VERSION ""

NS_ :

BS_:

BU_:

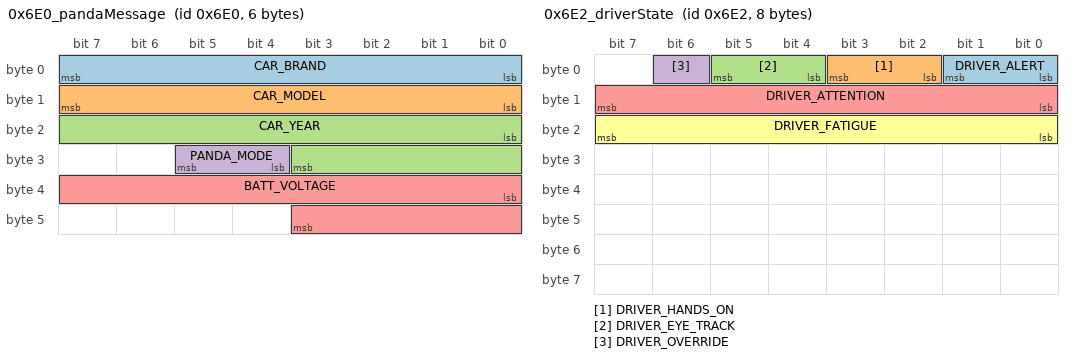
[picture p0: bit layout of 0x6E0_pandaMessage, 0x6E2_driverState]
BO_ 1760 0x6E0_pandaMessage: 6 Vector__XXX
 SG_ CAR_BRAND : 0|8@1+ (1,0) [0|255] "" Vector__XXX
 SG_ CAR_MODEL : 8|8@1+ (1,0) [0|255] "" Vector__XXX
 SG_ CAR_YEAR : 16|12@1+ (1,0) [0|4095] "" Vector__XXX
 SG_ PANDA_MODE : 28|2@1+ (1,0) [0|3] "" Vector__XXX
 SG_ BATT_VOLTAGE : 32|12@1+ (0.01,0) [0|40.95] "V" Vector__XXX

BO_ 1761 0x6E1_userCommand: 8 Vector__XXX
 SG_ BRAKE_PEDAL : 0|8@1+ (0.4,0) [0|102] "%" Vector__XXX
 SG_ GAS_PEDAL : 8|8@1+ (0.4,0) [0|102] "%" Vector__XXX
 SG_ STEER_ANGLE : 16|16@1+ (0.1,0) [-780|780] "deg" Vector__XXX
 SG_ YAW_RATE : 32|14@1+ (0.01,-81.91) [-81.91|81.91] "deg/s" Vector__XXX
 SG_ CRUISE_ENABLE : 46|1@1+ (1,0) [0|1] "" Vector__XXX
 SG_ LANE_ENABLE : 47|1@1+ (1,0) [0|1] "" Vector__XXX
 SG_ MADS_BUTTON : 48|1@1+ (1,0) [0|1] "" Vector__XXX
 SG_ CRUISE_SET : 49|1@1+ (1,0) [0|1] "" Vector__XXX
 SG_ CRUISE_CANCEL : 50|1@1+ (1,0) [0|1] "" Vector__XXX
 SG_ CRUISE_RESUME : 51|1@1+ (1,0) [0|1] "" Vector__XXX
 SG_ SPEED_UP_BTN : 52|1@1+ (1,0) [0|1] "" Vector__XXX
 SG_ SPEED_DOWN_BTN : 53|1@1+ (1,0) [0|1] "" Vector__XXX
 SG_ DISTANCE_NEAR_BTN : 54|1@1+ (1,0) [0|1] "" Vector__XXX
 SG_ DISTANCE_FAR_BTN : 55|1@1+ (1,0) [0|1] "" Vector__XXX
 SG_ HAZARD_BTN : 56|1@1+ (1,0) [0|1] "" Vector__XXX
 SG_ LEFT_BLINKER_BTN : 57|1@1+ (1,0) [0|1] "" Vector__XXX
 SG_ RIGHT_BLINKER_BTN : 58|1@1+ (1,0) [0|1] "" Vector__XXX
 SG_ ACCEL_PEDAL_PRESSED : 59|1@1+ (1,0) [0|1] "" Vector__XXX
 SG_ BRAKE_PEDAL_PRESSED : 60|1@1+ (1,0) [0|1] "" Vector__XXX
 SG_ STEER_WHEEL_PRESSED : 61|1@1+ (1,0) [0|1] "" Vector__XXX

BO_ 1762 0x6E2_driverState: 8 Vector__XXX
 SG_ DRIVER_ALERT : 0|2@1+ (1,0) [0|3] "" Vector__XXX
 SG_ DRIVER_HANDS_ON : 2|2@1+ (1,0) [0|3] "" Vector__XXX
 SG_ DRIVER_EYE_TRACK : 4|2@1+ (1,0) [0|3] "" Vector__XXX
 SG_ DRIVER_OVERRIDE : 6|1@1+ (1,0) [0|1] "" Vector__XXX
 SG_ DRIVER_ATTENTION : 8|8@1+ (0.4,0) [0|102] "%" Vector__XXX
 SG_ DRIVER_FATIGUE : 16|8@1+ (0.4,0) [0|102] "%" Vector__XXX

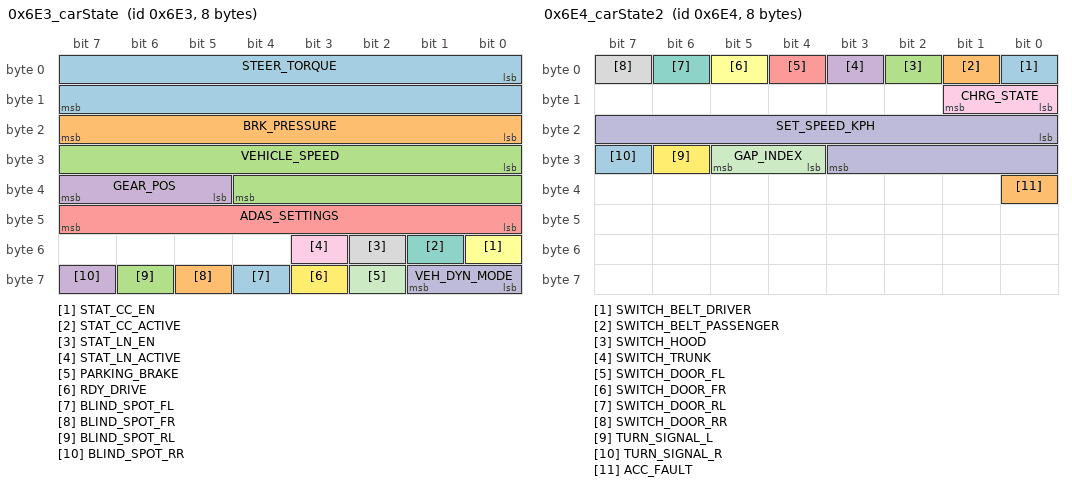
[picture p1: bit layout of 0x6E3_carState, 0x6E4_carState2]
BO_ 1763 0x6E3_carState: 8 Vector__XXX
 SG_ STEER_TORQUE : 0|16@1+ (0.1,-3276.8) [-3276.8|3276.7] "Nm" Vector__XXX
 SG_ BRK_PRESSURE : 16|8@1+ (0.1,0) [0|25.5] "bar" Vector__XXX
 SG_ VEHICLE_SPEED : 24|13@1+ (0.05625,0) [0|360] "km/h" Vector__XXX
 SG_ GEAR_POS : 37|3@1+ (1,0) [0|7] "" Vector__XXX
 SG_ ADAS_SETTINGS : 40|8@1+ (1,0) [0|255] "" Vector__XXX
 SG_ STAT_CC_EN : 48|1@1+ (1,0) [0|1] "" Vector__XXX
 SG_ STAT_CC_ACTIVE : 49|1@1+ (1,0) [0|1] "" Vector__XXX
 SG_ STAT_LN_EN : 50|1@1+ (1,0) [0|1] "" Vector__XXX
 SG_ STAT_LN_ACTIVE : 51|1@1+ (1,0) [0|1] "" Vector__XXX
 SG_ VEH_DYN_MODE : 56|2@1+ (1,0) [0|3] "" Vector__XXX
 SG_ PARKING_BRAKE : 58|1@1+ (1,0) [0|1] "" Vector__XXX
 SG_ RDY_DRIVE : 59|1@1+ (1,0) [0|1] "" Vector__XXX
 SG_ BLIND_SPOT_FL : 60|1@1+ (1,0) [0|1] "" Vector__XXX
 SG_ BLIND_SPOT_FR : 61|1@1+ (1,0) [0|1] "" Vector__XXX
 SG_ BLIND_SPOT_RL : 62|1@1+ (1,0) [0|1] "" Vector__XXX
 SG_ BLIND_SPOT_RR : 63|1@1+ (1,0) [0|1] "" Vector__XXX

BO_ 1764 0x6E4_carState2: 8 Vector__XXX
 SG_ SWITCH_BELT_DRIVER : 0|1@1+ (1,0) [0|1] "" Vector__XXX
 SG_ SWITCH_BELT_PASSENGER : 1|1@1+ (1,0) [0|1] "" Vector__XXX
 SG_ SWITCH_HOOD : 2|1@1+ (1,0) [0|1] "" Vector__XXX
 SG_ SWITCH_TRUNK : 3|1@1+ (1,0) [0|1] "" Vector__XXX
 SG_ SWITCH_DOOR_FL : 4|1@1+ (1,0) [0|1] "" Vector__XXX
 SG_ SWITCH_DOOR_FR : 5|1@1+ (1,0) [0|1] "" Vector__XXX
 SG_ SWITCH_DOOR_RL : 6|1@1+ (1,0) [0|1] "" Vector__XXX
 SG_ SWITCH_DOOR_RR : 7|1@1+ (1,0) [0|1] "" Vector__XXX
 SG_ CHRG_STATE : 8|2@1+ (1,0) [0|3] "" Vector__XXX
 SG_ SET_SPEED_KPH : 16|12@1+ (0.1,0) [0|409.5] "km/h" Vector__XXX
 SG_ GAP_INDEX : 28|2@1+ (1,1) [1|4] "" Vector__XXX
 SG_ TURN_SIGNAL_L : 30|1@1+ (1,0) [0|1] "" Vector__XXX
 SG_ TURN_SIGNAL_R : 31|1@1+ (1,0) [0|1] "" Vector__XXX
 SG_ ACC_FAULT : 32|1@1+ (1,0) [0|1] "" Vector__XXX

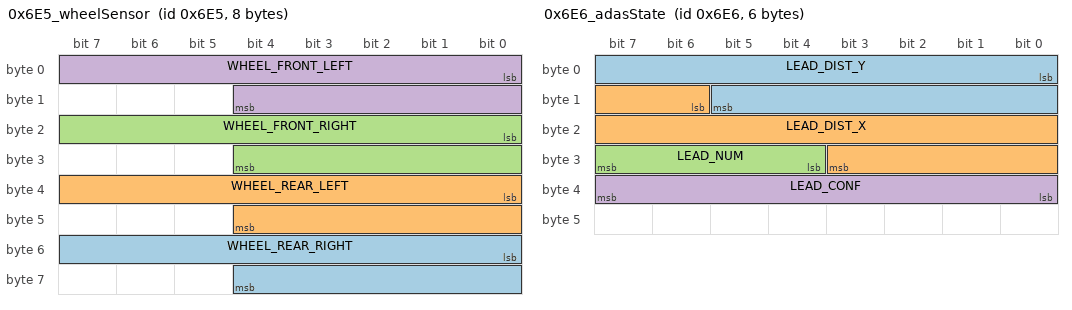
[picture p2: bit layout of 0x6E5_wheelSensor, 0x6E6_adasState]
BO_ 1765 0x6E5_wheelSensor: 8 Vector__XXX
 SG_ WHEEL_REAR_RIGHT : 48|13@1+ (0.05625,0) [0|360] "km/h" Vector__XXX
 SG_ WHEEL_REAR_LEFT : 32|13@1+ (0.05625,0) [0|360] "km/h" Vector__XXX
 SG_ WHEEL_FRONT_RIGHT : 16|13@1+ (0.05625,0) [0|360] "km/h" Vector__XXX
 SG_ WHEEL_FRONT_LEFT : 0|13@1+ (0.05625,0) [0|360] "km/h" Vector__XXX

BO_ 1766 0x6E6_adasState: 6 Vector__XXX
 SG_ LEAD_DIST_Y : 0|14@1+ (0.04,0) [0|655.32] "m" Vector__XXX
 SG_ LEAD_DIST_X : 14|14@1+ (0.04,0) [0|655.32] "m" Vector__XXX
 SG_ LEAD_NUM : 28|4@1+ (1,0) [0|3] "" Vector__XXX
 SG_ LEAD_CONF : 32|8@1+ (0.4,0) [0|102] "%" Vector__XXX

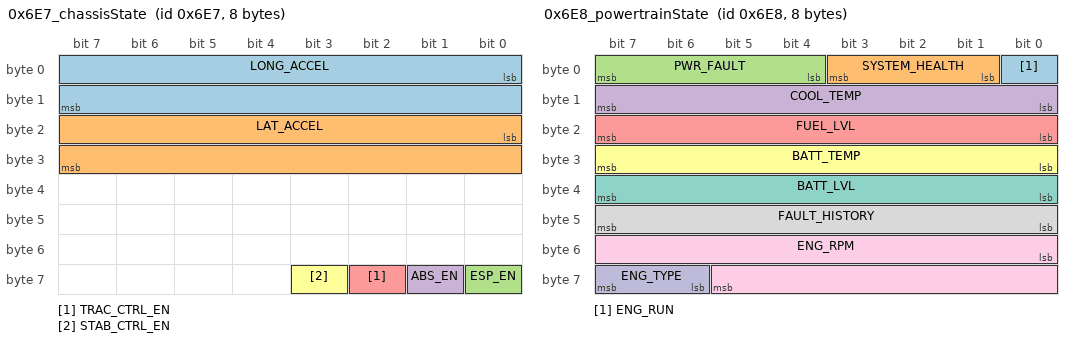
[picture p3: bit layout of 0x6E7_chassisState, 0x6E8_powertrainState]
BO_ 1767 0x6E7_chassisState: 8 Vector__XXX
 SG_ LONG_ACCEL : 0|16@1+ (0.001,-32.768) [-32.768|32.767] "m/s2" Vector__XXX
 SG_ LAT_ACCEL : 16|16@1+ (0.001,-32.768) [-32.768|32.767] "m/s2" Vector__XXX
 SG_ ESP_EN : 56|1@1+ (1,0) [0|1] "" Vector__XXX
 SG_ ABS_EN : 57|1@1+ (1,0) [0|1] "" Vector__XXX
 SG_ TRAC_CTRL_EN : 58|1@1+ (1,0) [0|1] "" Vector__XXX
 SG_ STAB_CTRL_EN : 59|1@1+ (1,0) [0|1] "" Vector__XXX

BO_ 1768 0x6E8_powertrainState: 8 Vector__XXX
 SG_ ENG_RUN : 0|1@1+ (1,0) [0|1] "" Vector__XXX
 SG_ SYSTEM_HEALTH : 1|3@1+ (1,0) [0|7] "" Vector__XXX
 SG_ PWR_FAULT : 4|4@1+ (1,0) [0|15] "" Vector__XXX
 SG_ COOL_TEMP : 8|8@1+ (1,-40) [-40|215] "C" Vector__XXX
 SG_ FUEL_LVL : 16|8@1+ (0.4,0) [0|102] "%" Vector__XXX
 SG_ BATT_TEMP : 24|8@1+ (1,-40) [-40|215] "C" Vector__XXX
 SG_ BATT_LVL : 32|8@1+ (0.4,0) [0|102] "%" Vector__XXX
 SG_ FAULT_HISTORY : 40|8@1+ (1,0) [0|255] "" Vector__XXX
 SG_ ENG_RPM : 48|14@1+ (0.25,0) [0|4095.75] "rpm" Vector__XXX
 SG_ ENG_TYPE : 62|2@1+ (1,0) [0|3] "" Vector__XXX

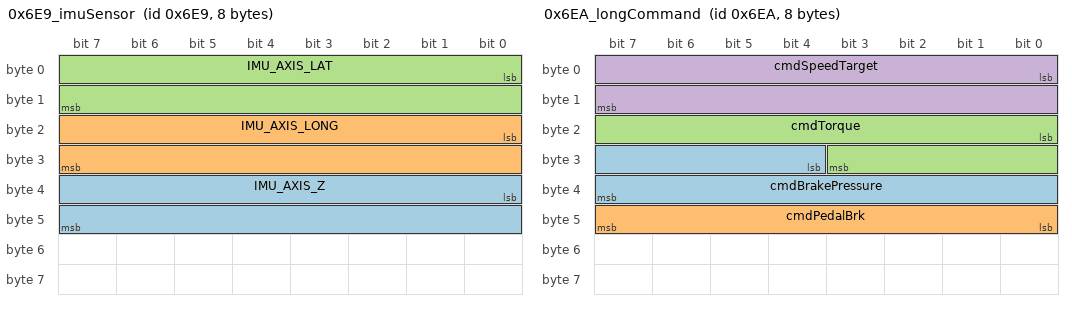
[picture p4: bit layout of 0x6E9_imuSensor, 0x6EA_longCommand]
BO_ 1769 0x6E9_imuSensor: 8 Vector__XXX
 SG_ IMU_AXIS_Z : 32|16@1+ (0.001,-32.768) [-32.768|32.767] "m/s2" Vector__XXX
 SG_ IMU_AXIS_LONG : 16|16@1+ (0.001,-32.768) [-32.768|32.767] "m/s2" Vector__XXX
 SG_ IMU_AXIS_LAT : 0|16@1+ (0.001,-32.768) [-32.768|32.767] "m/s2" Vector__XXX

BO_ 1770 0x6EA_longCommand: 8 Vector__XXX
 SG_ cmdBrakePressure : 28|12@1+ (0.015625,0) [0|1023.984375] "bar" Vector__XXX
 SG_ cmdPedalBrk : 40|8@1+ (0.4,0) [0|102] "%" Vector__XXX
 SG_ cmdTorque : 16|12@1+ (5,-5000) [-5000|15475] "NM" Vector__XXX
 SG_ cmdSpeedTarget : 0|16@1+ (0.01,0) [0|655.35] "km/h" Vector__XXX

BO_ 1771 0x6EB_longCommand2: 8 Vector__XXX
 SG_ cmdSpeedAccel : 0|8@1+ (0.05,-10) [-10|2.75] "m/s2" Vector__XXX
 SG_ cmdSpeedDecel : 8|8@1+ (0.05,-10) [-10|2.75] "m/s2" Vector__XXX
 SG_ cmdAccelTune : 16|4@1+ (1,0) [0|15] "" Vector__XXX
 SG_ cmdDecelTune : 20|4@1+ (1,0) [0|15] "" Vector__XXX
 SG_ cmdCruiseEnabled : 56|1@1+ (1,0) [0|1] "" Vector__XXX
 SG_ cmdCruiseActive : 57|1@1+ (1,0) [0|1] "" Vector__XXX
 SG_ cmdCruiseResume : 58|1@1+ (1,0) [0|1] "" Vector__XXX
 SG_ cmdCruiseSsEn : 59|1@1+ (1,0) [0|1] "" Vector__XXX
 SG_ cmdCruiseSsActive : 60|1@1+ (1,0) [0|1] "" Vector__XXX
 SG_ cmdRegenEn : 61|1@1+ (1,0) [0|1] "" Vector__XXX
 SG_ cmdRegenKer : 62|2@1+ (1,0) [0|3] "" Vector__XXX
 SG_ cmdAccControllable : 55|1@1+ (1,0) [0|1] "" Vector__XXX
 SG_ cmdAccOverride : 54|1@1+ (1,0) [0|1] "" Vector__XXX
 SG_ cmdStandstillResume : 53|1@1+ (1,0) [0|1] "" Vector__XXX
 SG_ cmdReqActiveLow : 52|1@1+ (1,0) [0|1] "" Vector__XXX
 SG_ cmdIdleStopEn : 51|1@1+ (1,0) [0|1] "" Vector__XXX
 SG_ cmdBrakeComp : 24|8@1+ (0.0039216,0) [0|1] "" Vector__XXX
 SG_ cmdFcwAlert : 32|1@1+ (1,0) [0|1] "" Vector__XXX
 SG_ cmdAebReq : 33|1@1+ (1,0) [0|1] "" Vector__XXX
 SG_ cmdBrakePump : 34|1@1+ (1,0) [0|1] "" Vector__XXX

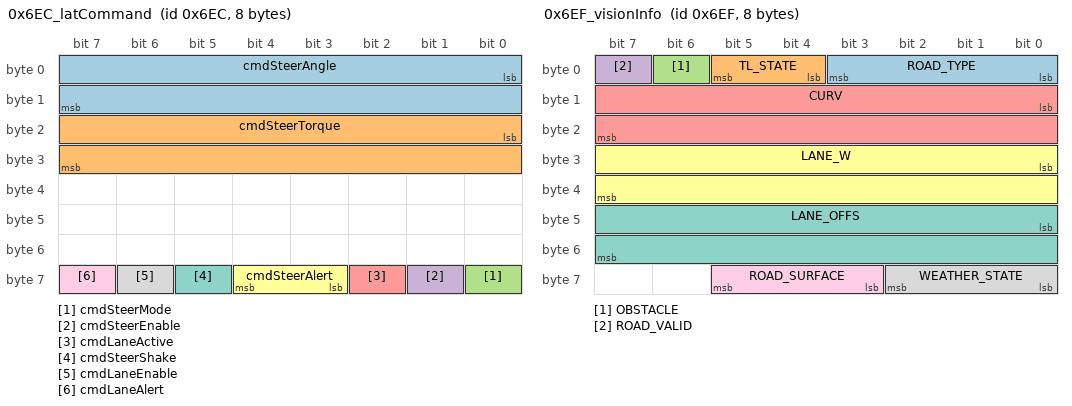
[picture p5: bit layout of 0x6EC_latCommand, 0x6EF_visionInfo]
BO_ 1772 0x6EC_latCommand: 8 Vector__XXX
 SG_ cmdSteerAngle : 0|16@1+ (0.1,-3276.8) [-3276.8|3276.7] "deg" Vector__XXX
 SG_ cmdSteerTorque : 16|16@1+ (0.01,-327.68) [-327.68|327.67] "Nm" Vector__XXX
 SG_ cmdSteerMode : 56|1@1+ (1,0) [0|1] "" Vector__XXX
 SG_ cmdSteerEnable : 57|1@1+ (1,0) [0|1] "" Vector__XXX
 SG_ cmdLaneActive : 58|1@1+ (1,0) [0|1] "" Vector__XXX
 SG_ cmdSteerAlert : 59|2@1+ (1,0) [0|3] "" Vector__XXX
 SG_ cmdSteerShake : 61|1@1+ (1,0) [0|1] "" Vector__XXX
 SG_ cmdLaneEnable : 62|1@1+ (1,0) [0|1] "" Vector__XXX
 SG_ cmdLaneAlert : 63|1@1+ (1,0) [0|1] "" Vector__XXX

BO_ 1776 0x6F0_latCommand2: 8 Vector__XXX

BO_ 1777 0x6F1_dispCommand: 8 Vector__XXX
 SG_ cmdDispCcEn : 0|1@1+ (1,0) [0|1] "" Vector__XXX
 SG_ cmdDispCcActive : 1|1@1+ (1,0) [0|1] "" Vector__XXX
 SG_ cmdDispLnEn : 2|1@1+ (1,0) [0|1] "" Vector__XXX
 SG_ cmdDispLnActive : 3|1@1+ (1,0) [0|1] "" Vector__XXX
 SG_ cmdDispSoundAlert : 4|1@1+ (1,0) [0|1] "" Vector__XXX
 SG_ cmdDispLeadC : 5|1@1+ (1,0) [0|1] "" Vector__XXX
 SG_ cmdDispLeadR : 6|1@1+ (1,0) [0|1] "" Vector__XXX
 SG_ cmdDispLeadL : 7|1@1+ (1,0) [0|1] "" Vector__XXX
 SG_ cmdDispDepartLeft : 8|1@1+ (1,0) [0|1] "" Vector__XXX
 SG_ cmdDispDepartRight : 9|1@1+ (1,0) [0|1] "" Vector__XXX
 SG_ cmdDispLane1 : 10|1@1+ (1,0) [0|1] "" Vector__XXX
 SG_ cmdDispLane2 : 11|1@1+ (1,0) [0|1] "" Vector__XXX
 SG_ cmdDispLane3 : 12|1@1+ (1,0) [0|1] "" Vector__XXX
 SG_ cmdDispLane4 : 13|1@1+ (1,0) [0|1] "" Vector__XXX
 SG_ cmdDispRoadEdgeLeft : 14|1@1+ (1,0) [0|1] "" Vector__XXX
 SG_ cmdDispRoadEdgeRight : 15|1@1+ (1,0) [0|1] "" Vector__XXX
 SG_ cmdDispFollowDistance : 16|2@1+ (1,0) [0|7] "" Vector__XXX
 SG_ cmdDispSpeed : 32|16@1+ (0.01,0) [0|655.35] "km/h" Vector__XXX
 SG_ cmdDispPassThrough : 48|16@1+ (1,0) [0|65535] "" Vector__XXX

BO_ 1775 0x6EF_visionInfo: 8 Vector__XXX
 SG_ ROAD_TYPE : 0|4@1+ (1,0) [0|15] "" Vector__XXX
 SG_ TL_STATE : 4|2@1+ (1,0) [0|3] "" Vector__XXX
 SG_ OBSTACLE : 6|1@1+ (1,0) [0|1] "" Vector__XXX
 SG_ ROAD_VALID : 7|1@1+ (1,0) [0|1] "" Vector__XXX
 SG_ CURV : 8|16@1+ (0.0001,-3.2768) [-3.2768|3.2767] "1/m" Vector__XXX
 SG_ LANE_W : 24|16@1+ (0.01,0) [0|655.35] "m" Vector__XXX
 SG_ LANE_OFFS : 40|16@1+ (0.01,-327.68) [-327.68|327.67] "m" Vector__XXX
 SG_ WEATHER_STATE : 56|3@1+ (1,0) [0|7] "" Vector__XXX
 SG_ ROAD_SURFACE : 59|3@1+ (1,0) [0|7] "" Vector__XXX

BO_ 1773 0x6ED_modelIdAtto3: 6 Vector__XXX
 SG_ MODEL_MARKER : 0|8@1+ (1,0) [0|255] "" Vector__XXX

BO_ 1774 0x6EE_modelIdDolphin: 4 Vector__XXX
 SG_ MODEL_MARKER : 0|8@1+ (1,0) [0|255] "" Vector__XXX

BO_ 1775 0x6EF_modelIdDeepal: 8 Vector__XXX
 SG_ MODEL_MARKER : 0|8@1+ (1,0) [0|255] "" Vector__XXX

BA_DEF_  "BusType" STRING ;
BA_DEF_  "DBName" STRING ;
BA_DEF_ BO_  "GenMsgCycleTime" INT 0 3600000;
BA_DEF_ SG_  "GenSigStartValue" FLOAT 0 0;
BA_DEF_DEF_  "BusType" "CAN";
BA_DEF_DEF_  "DBName" "BROWNPANDA";
BA_DEF_DEF_  "GenMsgCycleTime" 100;
BA_DEF_DEF_  "GenSigStartValue" 0;
BA_ "GenMsgCycleTime" BO_ 1761 10;
BA_ "GenMsgCycleTime" BO_ 1762 20;
BA_ "GenMsgCycleTime" BO_ 1763 10;
BA_ "GenMsgCycleTime" BO_ 1764 20;
BA_ "GenMsgCycleTime" BO_ 1765 50;
BA_ "GenMsgCycleTime" BO_ 1767 50;
BA_ "GenMsgCycleTime" BO_ 1768 20;
BA_ "GenMsgCycleTime" BO_ 1769 10;
BA_ "GenMsgCycleTime" BO_ 1770 10;
BA_ "GenMsgCycleTime" BO_ 1771 20;
BA_ "GenMsgCycleTime" BO_ 1772 10;
BA_ "GenMsgCycleTime" BO_ 1773 1000;
BA_ "GenMsgCycleTime" BO_ 1774 1000;
BA_ "GenMsgCycleTime" BO_ 1775 1000;
BA_ "GenMsgCycleTime" BO_ 1776 20;
BA_ "GenMsgCycleTime" BO_ 1777 20;
BA_ "GenSigStartValue" SG_ 1770 cmdTorque 1000;
BA_ "GenSigStartValue" SG_ 1771 cmdSpeedAccel -455.36;
BA_ "GenSigStartValue" SG_ 1771 cmdSpeedDecel -455.36;
VAL_ 1760 carBrand 0 "UNKNOWN" 1 "BYD" 2 "CHANGAN" 3 "GWM" 4 "GAC" 5 "SAIC" 6 "CHERY" 7 "ZEEKR" 8 "BAIC" 9 "TOYOTA" 10 "ISUZU" 11 "HONDA" 12 "MITSUBISHI" 13 "MERCEDES" 14 "BMW" 15 "PORSCHE" ;
VAL_ 1760 carModel 0 "UNKNOWN" 1 "BYD_SEAL" 2 "BYD_HAN" 3 "BYD_TANG" 4 "CHANGAN_UNI" 5 "GWM_ORA" 6 "GAC_AION" 7 "SAIC_MG" 8 "CHERY_TIGGO" 9 "ZEEKR_001" 10 "BAIC_EU" 11 "TOYOTA_CAMRY" 12 "ISUZU_DMAX" 13 "HONDA_ACCORD" 14 "MITSUBISHI_OUTLANDER" 15 "MERCEDES_C_CLASS" 16 "BMW_3_SERIES" 17 "PORSCHE_TAYCAN" ;
VAL_ 1760 pandaMode 0 "OEM_MODE" 1 "INTERRUPT_MODE" 2 "OVERRIDE_MODE" 3 "DIAGNOSTIC_MODE" ;
VAL_ 1761 CRUISE_ENABLE 0 "NOT_PRESSED" 1 "PRESSED" ;
VAL_ 1761 LANE_ENABLE 0 "NOT_PRESSED" 1 "PRESSED" ;
VAL_ 1761 MADS_BUTTON 0 "NOT_PRESSED" 1 "PRESSED" ;
VAL_ 1761 CRUISE_SET 0 "NOT_PRESSED" 1 "PRESSED" ;
VAL_ 1761 CRUISE_CANCEL 0 "NOT_PRESSED" 1 "PRESSED" ;
VAL_ 1761 CRUISE_RESUME 0 "NOT_PRESSED" 1 "PRESSED" ;
VAL_ 97 btnSpdUp 0 "NOT_PRESSED" 1 "PRESSED" ;
VAL_ 97 btnSpdDn 0 "NOT_PRESSED" 1 "PRESSED" ;
VAL_ 97 btnDistNr 0 "NOT_PRESSED" 1 "PRESSED" ;
VAL_ 97 btnDistFar 0 "NOT_PRESSED" 1 "PRESSED" ;
VAL_ 97 btnHazard 0 "OFF" 1 "ON" ;
VAL_ 97 btnBlinkL 0 "OFF" 1 "ON" ;
VAL_ 97 btnBlinkR 0 "OFF" 1 "ON" ;
VAL_ 97 actPedalPressed 0 "NOT_PRESSED" 1 "PRESSED" ;
VAL_ 97 actBrakePressed 0 "NOT_PRESSED" 1 "PRESSED" ;
VAL_ 97 actSteerPressed 0 "NOT_PRESSED" 1 "PRESSED" ;
VAL_ 98 driverAlert 0 "CRITICAL" 1 "WARNING" 2 "ATTENTION" 3 "NORMAL" ;
VAL_ 98 driverHandsOn 0 "HANDS_OFF" 1 "LIGHT_GRIP" 2 "FIRM_GRIP" 3 "TIGHT_GRIP" ;
VAL_ 98 driverEyeTrack 0 "EYES_OFF" 1 "DISTRACTED" 2 "FOCUSED" 3 "ALERT" ;
VAL_ 98 driverOverride 0 "NO_OVERRIDE" 1 "OVERRIDE_ACTIVE" ;
VAL_ 99 gearPos 0 "PARK" 1 "REVERSE" 2 "NEUTRAL" 3 "DRIVE" 4 "SPORT" 5 "LOW" 6 "MANUAL" 7 "RESERVED" ;
VAL_ 99 statCcEn 0 "DISABLED" 1 "ENABLED" ;
VAL_ 99 statCcActive 0 "INACTIVE" 1 "ACTIVE" ;
VAL_ 99 statLnEn 0 "DISABLED" 1 "ENABLED" ;
VAL_ 99 statLnActive 0 "INACTIVE" 1 "ACTIVE" ;
VAL_ 99 vehDynMode 0 "NORMAL" 1 "ECO" 2 "SPORT" 3 "OTHERS" ;
VAL_ 99 parkingBrake 0 "RELEASED" 1 "ENGAGED" ;
VAL_ 99 rdyDrive 0 "NOT_READY" 1 "READY" ;
VAL_ 99 blindSpotFL 0 "NO_VEHICLE" 1 "VEHICLE_DETECTED" ;
VAL_ 99 blindSpotFR 0 "NO_VEHICLE" 1 "VEHICLE_DETECTED" ;
VAL_ 99 blindSpotRL 0 "NO_VEHICLE" 1 "VEHICLE_DETECTED" ;
VAL_ 99 blindSpotRR 0 "NO_VEHICLE" 1 "VEHICLE_DETECTED" ;
VAL_ 100 switchBeltDriver 0 "UNBUCKLED" 1 "BUCKLED" ;
VAL_ 100 switchBeltPassenger 0 "UNBUCKLED" 1 "BUCKLED" ;
VAL_ 100 switchHood 0 "CLOSED" 1 "OPEN" ;
VAL_ 100 switchTrunk 0 "CLOSED" 1 "OPEN" ;
VAL_ 100 switchDoorFL 0 "CLOSED" 1 "OPEN" ;
VAL_ 100 switchDoorFR 0 "CLOSED" 1 "OPEN" ;
VAL_ 100 switchDoorRL 0 "CLOSED" 1 "OPEN" ;
VAL_ 100 switchDoorRR 0 "CLOSED" 1 "OPEN" ;
VAL_ 100 chrgState 0 "NOT_CHARGING" 1 "AC_CHARGING" 2 "DC_CHARGING" 3 "WIRELESS_CHARGING" ;
VAL_ 100 turnSignalL 0 "OFF" 1 "ON" ;
VAL_ 100 turnSignalR 0 "OFF" 1 "ON" ;
VAL_ 100 accFault 0 "NO_FAULT" 1 "FAULT" ;
VAL_ 100 gapIndex 1 "GAP1" 2 "GAP2" 3 "GAP3" 4 "GAP4" ;
VAL_ 102 leadNum 0 "NO_LEAD" 1 "LEAD_1" 2 "LEAD_2" 3 "MULTIPLE_LEADS" ;
VAL_ 103 espEn 0 "DISABLED" 1 "ENABLED" ;
VAL_ 103 absEn 0 "DISABLED" 1 "ENABLED" ;
VAL_ 103 tracCtrlEn 0 "DISABLED" 1 "ENABLED" ;
VAL_ 103 stabCtrlEn 0 "DISABLED" 1 "ENABLED" ;
VAL_ 104 engRun 0 "STOPPED" 1 "RUNNING" ;
VAL_ 104 pwrFault 0 "NO_FAULT" 1 "OVERHEAT" 2 "UNDERVOLTAGE" 3 "OVERVOLTAGE" 4 "OVERCURRENT" 5 "SENSOR_FAULT" 6 "COMMUNICATION_FAULT" 7 "SYSTEM_FAULT" 15 "UNKNOWN_FAULT" ;
VAL_ 104 engType 0 "ICE" 1 "HEV" 2 "BEV" 3 "FCEV" ;
VAL_ 104 systemHealth 0 "CRITICAL_FAULT" 1 "MAJOR_FAULT" 2 "MINOR_FAULT" 3 "DEGRADED" 4 "LIMITED" 5 "NORMAL" 6 "OPTIMAL" 7 "UNKNOWN" ;
VAL_ 107 cmdAccelTune 0 "MIN" 15 "MAX" ;
VAL_ 107 cmdDecelTune 0 "MIN" 15 "MAX" ;
VAL_ 107 cmdCruiseEnabled 0 "DISABLED" 1 "ENABLED" ;
VAL_ 107 cmdCruiseActive 0 "INACTIVE" 1 "ACTIVE" ;
VAL_ 107 cmdCruiseResume 0 "NOT_PRESSED" 1 "PRESSED" ;
VAL_ 107 cmdCruiseSsEn 0 "MOVING" 1 "STANDSTILL" ;
VAL_ 107 cmdCruiseSsActive 0 "MOVING" 1 "STANDSTILL" ;
VAL_ 107 cmdRegenEn 0 "DISABLED" 1 "ENABLED" ;
VAL_ 107 cmdRegenKer 0 "DISABLED" 1 "ENABLED" ;
VAL_ 108 cmdSteerMode 0 "MANUAL" 1 "ASSIST" ;
VAL_ 108 cmdSteerEnable 0 "DISABLED" 1 "ENABLED" ;
VAL_ 108 cmdLaneActive 0 "INACTIVE" 1 "ACTIVE" ;
VAL_ 108 cmdSteerAlert 0 "NO_ALERT" 1 "ATTENTION" 2 "WARNING" 3 "CRITICAL" ;
VAL_ 108 cmdSteerShake 0 "NO_SHAKE" 1 "SHAKE_ACTIVE" ;
VAL_ 108 cmdLaneEnable 0 "DISABLED" 1 "ENABLED" ;
VAL_ 108 cmdLaneAlert 0 "NO_ALERT" 1 "ALERT_ACTIVE" ;
VAL_ 110 cmdDispCcEn 0 "CRUISE_DISABLED" 1 "CRUISE_ENABLED" ;
VAL_ 110 cmdDispCcActive 0 "CRUISE_DISABLED" 1 "CRUISE_ENABLED" ;
VAL_ 110 cmdDispLnEn 0 "LANE_ASSIST_OFF" 1 "LANE_ASSIST_ON" ;
VAL_ 110 cmdDispLnActive 0 "CRUISE_DISABLED" 1 "CRUISE_ENABLED" ;
VAL_ 110 cmdDispSoundAlert 0 "NO_ALERT" 1 "ALERT_ACTIVE" ;
VAL_ 110 cmdDispLeadC 0 "NO_LEAD" 1 "LEAD_DETECTED" ;
VAL_ 110 cmdDispLeadR 0 "NO_LEAD" 1 "LEAD_DETECTED" ;
VAL_ 110 cmdDispLeadL 0 "NO_LEAD" 1 "LEAD_DETECTED" ;
VAL_ 110 cmdDispDepartLeft 0 "NO_DEPARTURE" 1 "DEPARTING_LEFT" ;
VAL_ 110 cmdDispDepartRight 0 "NO_DEPARTURE" 1 "DEPARTING_RIGHT" ;
VAL_ 110 cmdDispLane1 0 "NO_LANE" 1 "SOLID_LINE" 2 "DASHED_LINE" ;
VAL_ 110 cmdDispLane2 0 "NO_LANE" 1 "SOLID_LINE" 2 "DASHED_LINE" ;
VAL_ 110 cmdDispLane3 0 "NO_LANE" 1 "SOLID_LINE" 2 "DASHED_LINE" ;
VAL_ 110 cmdDispLane4 0 "NO_LANE" 1 "SOLID_LINE" 2 "DASHED_LINE" ;
VAL_ 110 cmdDispRoadEdgeLeft 0 "NO_LANE" 1 "SOLID_LINE" 2 "DASHED_LINE" ;
VAL_ 110 cmdDispRoadEdgeRight 0 "NO_LANE" 1 "SOLID_LINE" 2 "DASHED_LINE" ;
VAL_ 110 cmdDispFollowDistance 0 "VERY_CLOSE" 1 "CLOSE" 2 "MEDIUM" 3 "FAR" 4 "VERY_FAR" 5 "EXTRA_FAR" 6 "MAXIMUM" 7 "AUTO" ;
VAL_ 111 ROAD_TYPE 0 "UNKNOWN" 1 "HIGHWAY" 2 "CITY_STREET" 3 "PARKING_LOT" 4 "TUNNEL" 5 "BRIDGE" 6 "ROUNDABOUT" 7 "INTERSECTION" 8 "CONSTRUCTION" 9 "SCHOOL_ZONE" 10 "TOLL_BOOTH" 11 "SERVICE_AREA" 12 "RAMP" 13 "PRIVATE_ROAD" 14 "EMERGENCY_LANE" 15 "INVALID" ;
VAL_ 111 TL_STATE 0 "UNKNOWN" 1 "GREEN" 2 "YELLOW" 3 "RED" ;
VAL_ 111 OBSTACLE 0 "NO_OBSTACLE" 1 "OBSTACLE_DETECTED" ;
VAL_ 111 ROAD_VALID 0 "INVALID" 1 "VALID" ;
VAL_ 111 weatherState 0 "UNKNOWN" 1 "CLEAR" 2 "CLOUDY" 3 "LIGHT_RAIN" 4 "HEAVY_RAIN" 5 "SNOW" 6 "FOG" 7 "EXTREME" ;
VAL_ 111 roadSurface 0 "UNKNOWN" 1 "DRY" 2 "WET" 3 "ICE" 4 "SNOW" 5 "GRAVEL" 6 "DIRT" 7 "CONSTRUCTION" ;
